# CTRL_MODULE_CORE register map
Vendor: Texas Instruments
Registers are 32-bit, access per field, reset 0x0 unless marked. A register's access mark holds for its fields unless they carry their own. Offsets are as the file gives them; [hi:lo] are bit positions; {n}, {i} and the like mark numbered series; 'fields as' and 'values as' point back to an identical list.

## CTRL_MODULE_CORE (part 5 of 12)
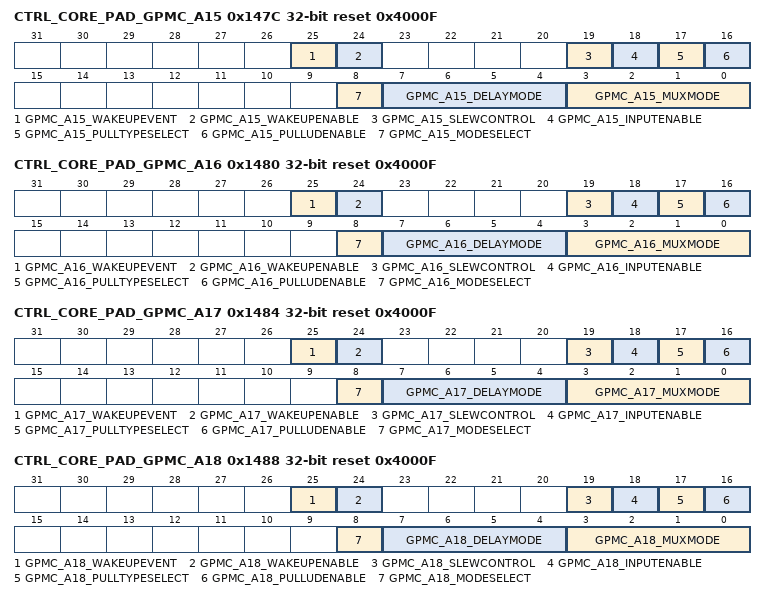
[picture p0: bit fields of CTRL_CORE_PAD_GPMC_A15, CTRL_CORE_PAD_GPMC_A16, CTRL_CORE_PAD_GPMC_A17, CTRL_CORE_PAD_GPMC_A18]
0x147C CTRL_CORE_PAD_GPMC_A15 reset 0x4000F
  [25] GPMC_A15_WAKEUPEVENT ro
    0=NOWAKEUP (No wakeup event detected); 1=WAKEUP (Wakeup event detected)
  [24] GPMC_A15_WAKEUPENABLE rw
    0=DISABLE (Wakeup is disabled); 1=ENABLE (Wakeup is enabled)
  [19] GPMC_A15_SLEWCONTROL rw
    0=FAST_SLEW (Fast slew is selected); 1=SLOW_SLEW (Slow slew is selected)
  [18] GPMC_A15_INPUTENABLE rw
    0=DISABLE (Receive mode is disabled); 1=ENABLE (Receive mode is enabled)
  [17] GPMC_A15_PULLTYPESELECT rw
    0=PULL_DOWN (Pull Down is selected); 1=PULL_UP (Pull Up is selected)
  [16] GPMC_A15_PULLUDENABLE rw
    0=ENABLE (Enables weak Pull Up/Down); 1=DISABLE (Disables weak Pull Up/Down)
  [8] GPMC_A15_MODESELECT rw — Selects between the Default IO Timing Mode and a Virtual or Manual IO Timing Mode. Refer to the device Data Manual for definition of the required settings for a given mode of operation. When this bit is 0b1, a Virtual IO Timing Mode can be selected via the DELAYMODE field of this register, as described in, Virtual IO Timing Modes. Manual IO Timing Modes are selected via the procedure described in , Manual IO Timing Modes.
    0=MUX_MODE (Default IO Timing Mode is used); 1=DELAY_MODE (A Virtual or Manual IO Timing Mode is used)
  [7:4] GPMC_A15_DELAYMODE rw — This bit field selects the Virtual Timing Mode used when the MODESELECT bit is set to 0b1. See, Virtual IO Timing Modes for details.
  [3:0] GPMC_A15_MUXMODE rw
    0=GPMC_A15; 1=QSPI1_D2; 4=VIN4A_D8; 7=TIMER5; 14=GPIO2_5; 15=DRIVER OFF
0x1480 CTRL_CORE_PAD_GPMC_A16 reset 0x4000F
  [25] GPMC_A16_WAKEUPEVENT ro
    values as CTRL_CORE_PAD_GPMC_A15.GPMC_A15_WAKEUPEVENT
  [24] GPMC_A16_WAKEUPENABLE rw
    0=DISABLE (Wakeup is disabled); 1=ENABLE (Wakeup is enabled)
  [19] GPMC_A16_SLEWCONTROL rw
    values as CTRL_CORE_PAD_GPMC_A15.GPMC_A15_SLEWCONTROL
  [18] GPMC_A16_INPUTENABLE rw
    values as CTRL_CORE_PAD_GPMC_A15.GPMC_A15_INPUTENABLE
  [17] GPMC_A16_PULLTYPESELECT rw
    values as CTRL_CORE_PAD_GPMC_A15.GPMC_A15_PULLTYPESELECT
  [16] GPMC_A16_PULLUDENABLE rw
    values as CTRL_CORE_PAD_GPMC_A15.GPMC_A15_PULLUDENABLE
  [8] GPMC_A16_MODESELECT rw — Selects between the Default IO Timing Mode and a Virtual or Manual IO Timing Mode. Refer to the device Data Manual for definition of the required settings for a given mode of operation. When this bit is 0b1, a Virtual IO Timing Mode can be selected via the DELAYMODE field of this register, as described in, Virtual IO Timing Modes. Manual IO Timing Modes are selected via the procedure described in , Manual IO Timing Modes.
    values as CTRL_CORE_PAD_GPMC_A15.GPMC_A15_MODESELECT
  [7:4] GPMC_A16_DELAYMODE rw — This bit field selects the Virtual Timing Mode used when the MODESELECT bit is set to 0b1. See, Virtual IO Timing Modes for details.
  [3:0] GPMC_A16_MUXMODE rw
    0=GPMC_A16; 1=QSPI1_D0; 4=VIN4A_D9; 14=GPIO2_6; 15=DRIVER OFF
0x1484 CTRL_CORE_PAD_GPMC_A17 reset 0x4000F
  [25] GPMC_A17_WAKEUPEVENT ro
    values as CTRL_CORE_PAD_GPMC_A15.GPMC_A15_WAKEUPEVENT
  [24] GPMC_A17_WAKEUPENABLE rw
    0=DISABLE (Wakeup is disabled); 1=ENABLE (Wakeup is enabled)
  [19] GPMC_A17_SLEWCONTROL rw
    values as CTRL_CORE_PAD_GPMC_A15.GPMC_A15_SLEWCONTROL
  [18] GPMC_A17_INPUTENABLE rw
    values as CTRL_CORE_PAD_GPMC_A15.GPMC_A15_INPUTENABLE
  [17] GPMC_A17_PULLTYPESELECT rw
    values as CTRL_CORE_PAD_GPMC_A15.GPMC_A15_PULLTYPESELECT
  [16] GPMC_A17_PULLUDENABLE rw
    values as CTRL_CORE_PAD_GPMC_A15.GPMC_A15_PULLUDENABLE
  [8] GPMC_A17_MODESELECT rw — Selects between the Default IO Timing Mode and a Virtual or Manual IO Timing Mode. Refer to the device Data Manual for definition of the required settings for a given mode of operation. When this bit is 0b1, a Virtual IO Timing Mode can be selected via the DELAYMODE field of this register, as described in, Virtual IO Timing Modes. Manual IO Timing Modes are selected via the procedure described in , Manual IO Timing Modes.
    values as CTRL_CORE_PAD_GPMC_A15.GPMC_A15_MODESELECT
  [7:4] GPMC_A17_DELAYMODE rw — This bit field selects the Virtual Timing Mode used when the MODESELECT bit is set to 0b1. See, Virtual IO Timing Modes for details.
  [3:0] GPMC_A17_MUXMODE rw
    0=GPMC_A17; 1=QSPI1_D1; 4=VIN4A_D10; 14=GPIO2_7; 15=DRIVER OFF
0x1488 CTRL_CORE_PAD_GPMC_A18 reset 0x4000F
  [25] GPMC_A18_WAKEUPEVENT ro
    values as CTRL_CORE_PAD_GPMC_A15.GPMC_A15_WAKEUPEVENT
  [24] GPMC_A18_WAKEUPENABLE rw
    0=DISABLE (Wakeup is disabled); 1=ENABLE (Wakeup is enabled)
  [19] GPMC_A18_SLEWCONTROL rw
    values as CTRL_CORE_PAD_GPMC_A15.GPMC_A15_SLEWCONTROL
  [18] GPMC_A18_INPUTENABLE rw
    values as CTRL_CORE_PAD_GPMC_A15.GPMC_A15_INPUTENABLE
  [17] GPMC_A18_PULLTYPESELECT rw
    values as CTRL_CORE_PAD_GPMC_A15.GPMC_A15_PULLTYPESELECT
  [16] GPMC_A18_PULLUDENABLE rw
    values as CTRL_CORE_PAD_GPMC_A15.GPMC_A15_PULLUDENABLE
  [8] GPMC_A18_MODESELECT rw — Selects between the Default IO Timing Mode and a Virtual or Manual IO Timing Mode. Refer to the device Data Manual for definition of the required settings for a given mode of operation. When this bit is 0b1, a Virtual IO Timing Mode can be selected via the DELAYMODE field of this register, as described in, Virtual IO Timing Modes. Manual IO Timing Modes are selected via the procedure described in , Manual IO Timing Modes.
    values as CTRL_CORE_PAD_GPMC_A15.GPMC_A15_MODESELECT
  [7:4] GPMC_A18_DELAYMODE rw — This bit field selects the Virtual Timing Mode used when the MODESELECT bit is set to 0b1. See, Virtual IO Timing Modes for details.
  [3:0] GPMC_A18_MUXMODE rw
    0=GPMC_A18; 1=QSPI1_SCLK; 4=VIN4A_D11; 14=GPIO2_8; 15=DRIVER OFF
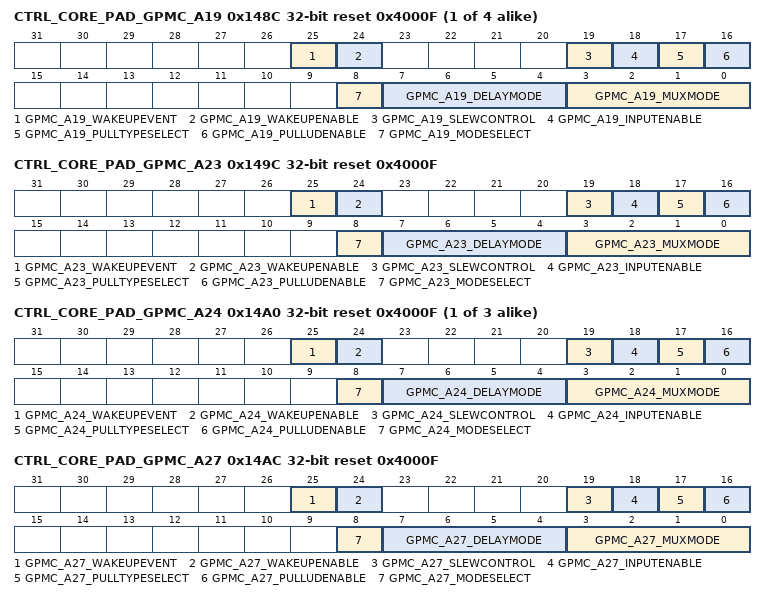
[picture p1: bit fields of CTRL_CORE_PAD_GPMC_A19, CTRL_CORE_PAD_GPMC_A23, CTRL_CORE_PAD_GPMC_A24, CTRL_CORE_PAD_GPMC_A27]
{0x1440+4i} CTRL_CORE_PAD_GPMC_A{i} reset 0x4000F (i=19..22)
  [25] GPMC_A{i}_WAKEUPEVENT ro
    values as CTRL_CORE_PAD_GPMC_A15.GPMC_A15_WAKEUPEVENT
  [24] GPMC_A{i}_WAKEUPENABLE rw
    0=DISABLE (Wakeup is disabled); 1=ENABLE (Wakeup is enabled)
  [19] GPMC_A{i}_SLEWCONTROL rw
    values as CTRL_CORE_PAD_GPMC_A15.GPMC_A15_SLEWCONTROL
  [18] GPMC_A{i}_INPUTENABLE rw
    values as CTRL_CORE_PAD_GPMC_A15.GPMC_A15_INPUTENABLE
  [17] GPMC_A{i}_PULLTYPESELECT rw
    values as CTRL_CORE_PAD_GPMC_A15.GPMC_A15_PULLTYPESELECT
  [16] GPMC_A{i}_PULLUDENABLE rw
    values as CTRL_CORE_PAD_GPMC_A15.GPMC_A15_PULLUDENABLE
  [8] GPMC_A{i}_MODESELECT rw — Selects between the Default IO Timing Mode and a Virtual or Manual IO Timing Mode. Refer to the device Data Manual for definition of the required settings for a given mode of operation. When this bit is 0b1, a Virtual IO Timing Mode can be selected via the DELAYMODE field of this register, as described in, Virtual IO Timing Modes. Manual IO Timing Modes are selected via the procedure described in , Manual IO Timing Modes.
    values as CTRL_CORE_PAD_GPMC_A15.GPMC_A15_MODESELECT
  [7:4] GPMC_A{i}_DELAYMODE rw — This bit field selects the Virtual Timing Mode used when the MODESELECT bit is set to 0b1. See, Virtual IO Timing Modes for details.
  [3:0] GPMC_A{i}_MUXMODE rw
    0=GPMC_A{i}; 1=MMC2_DAT{i-15}; 2=GPMC_A{i-6}; 4=VIN4A_D{i-7}; 6=VIN3B_D{i-19}; 14=GPIO2_{i-10}; 15=DRIVER OFF
0x149C CTRL_CORE_PAD_GPMC_A23 reset 0x4000F
  [25] GPMC_A23_WAKEUPEVENT ro
    values as CTRL_CORE_PAD_GPMC_A15.GPMC_A15_WAKEUPEVENT
  [24] GPMC_A23_WAKEUPENABLE rw
    0=DISABLE (Wakeup is disabled); 1=ENABLE (Wakeup is enabled)
  [19] GPMC_A23_SLEWCONTROL rw
    values as CTRL_CORE_PAD_GPMC_A15.GPMC_A15_SLEWCONTROL
  [18] GPMC_A23_INPUTENABLE rw
    values as CTRL_CORE_PAD_GPMC_A15.GPMC_A15_INPUTENABLE
  [17] GPMC_A23_PULLTYPESELECT rw
    values as CTRL_CORE_PAD_GPMC_A15.GPMC_A15_PULLTYPESELECT
  [16] GPMC_A23_PULLUDENABLE rw
    values as CTRL_CORE_PAD_GPMC_A15.GPMC_A15_PULLUDENABLE
  [8] GPMC_A23_MODESELECT rw — Selects between the Default IO Timing Mode and a Virtual or Manual IO Timing Mode. Refer to the device Data Manual for definition of the required settings for a given mode of operation. When this bit is 0b1, a Virtual IO Timing Mode can be selected via the DELAYMODE field of this register, as described in, Virtual IO Timing Modes. Manual IO Timing Modes are selected via the procedure described in , Manual IO Timing Modes.
    values as CTRL_CORE_PAD_GPMC_A15.GPMC_A15_MODESELECT
  [7:4] GPMC_A23_DELAYMODE rw — This bit field selects the Virtual Timing Mode used when the MODESELECT bit is set to 0b1. See, Virtual IO Timing Modes for details.
  [3:0] GPMC_A23_MUXMODE rw
    0=GPMC_A23; 1=MMC2_CLK; 2=GPMC_A17; 4=VIN4A_FLD0; 6=VIN3B_D4; 14=GPIO2_13; 15=DRIVER OFF
{0x1440+4i} CTRL_CORE_PAD_GPMC_A{i} reset 0x4000F (i=24..26)
  [25] GPMC_A{i}_WAKEUPEVENT ro
    values as CTRL_CORE_PAD_GPMC_A15.GPMC_A15_WAKEUPEVENT
  [24] GPMC_A{i}_WAKEUPENABLE rw
    0=DISABLE (Wakeup is disabled); 1=ENABLE (Wakeup is enabled)
  [19] GPMC_A{i}_SLEWCONTROL rw
    values as CTRL_CORE_PAD_GPMC_A15.GPMC_A15_SLEWCONTROL
  [18] GPMC_A{i}_INPUTENABLE rw
    values as CTRL_CORE_PAD_GPMC_A15.GPMC_A15_INPUTENABLE
  [17] GPMC_A{i}_PULLTYPESELECT rw
    values as CTRL_CORE_PAD_GPMC_A15.GPMC_A15_PULLTYPESELECT
  [16] GPMC_A{i}_PULLUDENABLE rw
    values as CTRL_CORE_PAD_GPMC_A15.GPMC_A15_PULLUDENABLE
  [8] GPMC_A{i}_MODESELECT rw — Selects between the Default IO Timing Mode and a Virtual or Manual IO Timing Mode. Refer to the device Data Manual for definition of the required settings for a given mode of operation. When this bit is 0b1, a Virtual IO Timing Mode can be selected via the DELAYMODE field of this register, as described in, Virtual IO Timing Modes. Manual IO Timing Modes are selected via the procedure described in , Manual IO Timing Modes.
    values as CTRL_CORE_PAD_GPMC_A15.GPMC_A15_MODESELECT
  [7:4] GPMC_A{i}_DELAYMODE rw — This bit field selects the Virtual Timing Mode used when the MODESELECT bit is set to 0b1. See, Virtual IO Timing Modes for details.
  [3:0] GPMC_A{i}_MUXMODE rw
    0=GPMC_A{i}; 1=MMC2_DAT{i-24}; 2=GPMC_A{i-6}; 6=VIN3B_D{i-19}; 14=GPIO2_{i-10}; 15=DRIVER OFF
0x14AC CTRL_CORE_PAD_GPMC_A27 reset 0x4000F
  [25] GPMC_A27_WAKEUPEVENT ro
    values as CTRL_CORE_PAD_GPMC_A15.GPMC_A15_WAKEUPEVENT
  [24] GPMC_A27_WAKEUPENABLE rw
    0=DISABLE (Wakeup is disabled); 1=ENABLE (Wakeup is enabled)
  [19] GPMC_A27_SLEWCONTROL rw
    values as CTRL_CORE_PAD_GPMC_A15.GPMC_A15_SLEWCONTROL
  [18] GPMC_A27_INPUTENABLE rw
    values as CTRL_CORE_PAD_GPMC_A15.GPMC_A15_INPUTENABLE
  [17] GPMC_A27_PULLTYPESELECT rw
    values as CTRL_CORE_PAD_GPMC_A15.GPMC_A15_PULLTYPESELECT
  [16] GPMC_A27_PULLUDENABLE rw
    values as CTRL_CORE_PAD_GPMC_A15.GPMC_A15_PULLUDENABLE
  [8] GPMC_A27_MODESELECT rw — Selects between the Default IO Timing Mode and a Virtual or Manual IO Timing Mode. Refer to the device Data Manual for definition of the required settings for a given mode of operation. When this bit is 0b1, a Virtual IO Timing Mode can be selected via the DELAYMODE field of this register, as described in, Virtual IO Timing Modes. Manual IO Timing Modes are selected via the procedure described in , Manual IO Timing Modes.
    values as CTRL_CORE_PAD_GPMC_A15.GPMC_A15_MODESELECT
  [7:4] GPMC_A27_DELAYMODE rw — This bit field selects the Virtual Timing Mode used when the MODESELECT bit is set to 0b1. See, Virtual IO Timing Modes for details.
  [3:0] GPMC_A27_MUXMODE rw
    0=GPMC_A27; 1=MMC2_DAT3; 2=GPMC_A21; 6=VIN3B_HSYNC1; 14=GPIO2_17; 15=DRIVER OFF
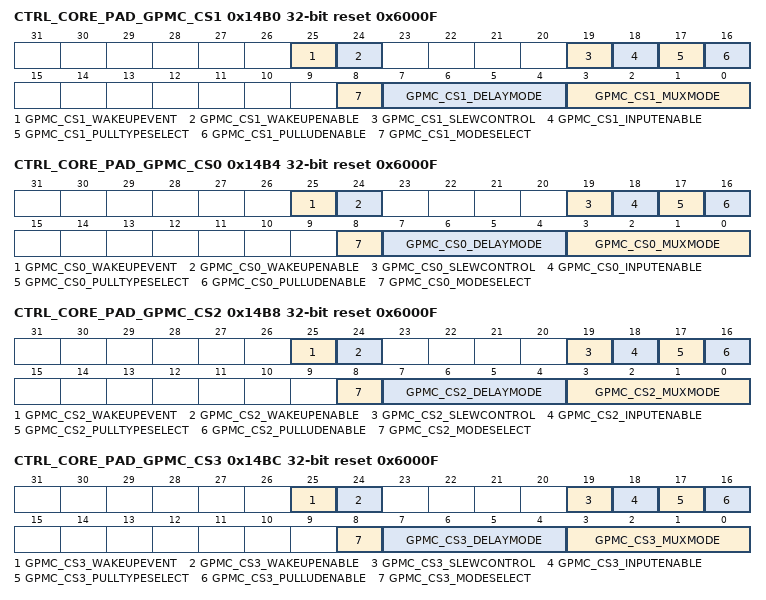
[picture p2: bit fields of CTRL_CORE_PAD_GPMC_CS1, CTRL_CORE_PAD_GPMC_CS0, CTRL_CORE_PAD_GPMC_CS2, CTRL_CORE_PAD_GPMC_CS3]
0x14B0 CTRL_CORE_PAD_GPMC_CS1 reset 0x6000F
  [25] GPMC_CS1_WAKEUPEVENT ro
    values as CTRL_CORE_PAD_GPMC_A15.GPMC_A15_WAKEUPEVENT
  [24] GPMC_CS1_WAKEUPENABLE rw
    0=DISABLE (Wakeup is disabled); 1=ENABLE (Wakeup is enabled)
  [19] GPMC_CS1_SLEWCONTROL rw
    values as CTRL_CORE_PAD_GPMC_A15.GPMC_A15_SLEWCONTROL
  [18] GPMC_CS1_INPUTENABLE rw
    values as CTRL_CORE_PAD_GPMC_A15.GPMC_A15_INPUTENABLE
  [17] GPMC_CS1_PULLTYPESELECT rw
    values as CTRL_CORE_PAD_GPMC_A15.GPMC_A15_PULLTYPESELECT
  [16] GPMC_CS1_PULLUDENABLE rw
    values as CTRL_CORE_PAD_GPMC_A15.GPMC_A15_PULLUDENABLE
  [8] GPMC_CS1_MODESELECT rw — Selects between the Default IO Timing Mode and a Virtual or Manual IO Timing Mode. Refer to the device Data Manual for definition of the required settings for a given mode of operation. When this bit is 0b1, a Virtual IO Timing Mode can be selected via the DELAYMODE field of this register, as described in, Virtual IO Timing Modes. Manual IO Timing Modes are selected via the procedure described in , Manual IO Timing Modes.
    values as CTRL_CORE_PAD_GPMC_A15.GPMC_A15_MODESELECT
  [7:4] GPMC_CS1_DELAYMODE rw — This bit field selects the Virtual Timing Mode used when the MODESELECT bit is set to 0b1. See, Virtual IO Timing Modes for details.
  [3:0] GPMC_CS1_MUXMODE rw
    0=GPMC_CS1; 1=MMC2_CMD; 2=GPMC_A22; 4=VIN4A_DE0; 6=VIN3B_VSYNC1; 14=GPIO2_18; 15=DRIVER OFF
0x14B4 CTRL_CORE_PAD_GPMC_CS0 reset 0x6000F
  [25] GPMC_CS0_WAKEUPEVENT ro
    values as CTRL_CORE_PAD_GPMC_A15.GPMC_A15_WAKEUPEVENT
  [24] GPMC_CS0_WAKEUPENABLE rw
    0=DISABLE (Wakeup is disabled); 1=ENABLE (Wakeup is enabled)
  [19] GPMC_CS0_SLEWCONTROL rw
    values as CTRL_CORE_PAD_GPMC_A15.GPMC_A15_SLEWCONTROL
  [18] GPMC_CS0_INPUTENABLE rw
    values as CTRL_CORE_PAD_GPMC_A15.GPMC_A15_INPUTENABLE
  [17] GPMC_CS0_PULLTYPESELECT rw
    values as CTRL_CORE_PAD_GPMC_A15.GPMC_A15_PULLTYPESELECT
  [16] GPMC_CS0_PULLUDENABLE rw
    values as CTRL_CORE_PAD_GPMC_A15.GPMC_A15_PULLUDENABLE
  [8] GPMC_CS0_MODESELECT rw — Selects between the Default IO Timing Mode and a Virtual or Manual IO Timing Mode. Refer to the device Data Manual for definition of the required settings for a given mode of operation. When this bit is 0b1, a Virtual IO Timing Mode can be selected via the DELAYMODE field of this register, as described in, Virtual IO Timing Modes. Manual IO Timing Modes are selected via the procedure described in , Manual IO Timing Modes.
    values as CTRL_CORE_PAD_GPMC_A15.GPMC_A15_MODESELECT
  [7:4] GPMC_CS0_DELAYMODE rw — This bit field selects the Virtual Timing Mode used when the MODESELECT bit is set to 0b1. See, Virtual IO Timing Modes for details.
  [3:0] GPMC_CS0_MUXMODE rw
    0=GPMC_CS0; 14=GPIO2_19; 15=DRIVER OFF
0x14B8 CTRL_CORE_PAD_GPMC_CS2 reset 0x6000F
  [25] GPMC_CS2_WAKEUPEVENT ro
    values as CTRL_CORE_PAD_GPMC_A15.GPMC_A15_WAKEUPEVENT
  [24] GPMC_CS2_WAKEUPENABLE rw
    0=DISABLE (Wakeup is disabled); 1=ENABLE (Wakeup is enabled)
  [19] GPMC_CS2_SLEWCONTROL rw
    values as CTRL_CORE_PAD_GPMC_A15.GPMC_A15_SLEWCONTROL
  [18] GPMC_CS2_INPUTENABLE rw
    values as CTRL_CORE_PAD_GPMC_A15.GPMC_A15_INPUTENABLE
  [17] GPMC_CS2_PULLTYPESELECT rw
    values as CTRL_CORE_PAD_GPMC_A15.GPMC_A15_PULLTYPESELECT
  [16] GPMC_CS2_PULLUDENABLE rw
    values as CTRL_CORE_PAD_GPMC_A15.GPMC_A15_PULLUDENABLE
  [8] GPMC_CS2_MODESELECT rw — Selects between the Default IO Timing Mode and a Virtual or Manual IO Timing Mode. Refer to the device Data Manual for definition of the required settings for a given mode of operation. When this bit is 0b1, a Virtual IO Timing Mode can be selected via the DELAYMODE field of this register, as described in, Virtual IO Timing Modes. Manual IO Timing Modes are selected via the procedure described in , Manual IO Timing Modes.
    values as CTRL_CORE_PAD_GPMC_A15.GPMC_A15_MODESELECT
  [7:4] GPMC_CS2_DELAYMODE rw — This bit field selects the Virtual Timing Mode used when the MODESELECT bit is set to 0b1. See, Virtual IO Timing Modes for details.
  [3:0] GPMC_CS2_MUXMODE rw
    0=GPMC_CS2; 1=QSPI1_CS0; 14=GPIO2_20; 15=DRIVER OFF
0x14BC CTRL_CORE_PAD_GPMC_CS3 reset 0x6000F
  [25] GPMC_CS3_WAKEUPEVENT ro
    values as CTRL_CORE_PAD_GPMC_A15.GPMC_A15_WAKEUPEVENT
  [24] GPMC_CS3_WAKEUPENABLE rw
    0=DISABLE (Wakeup is disabled); 1=ENABLE (Wakeup is enabled)
  [19] GPMC_CS3_SLEWCONTROL rw
    values as CTRL_CORE_PAD_GPMC_A15.GPMC_A15_SLEWCONTROL
  [18] GPMC_CS3_INPUTENABLE rw
    values as CTRL_CORE_PAD_GPMC_A15.GPMC_A15_INPUTENABLE
  [17] GPMC_CS3_PULLTYPESELECT rw
    values as CTRL_CORE_PAD_GPMC_A15.GPMC_A15_PULLTYPESELECT
  [16] GPMC_CS3_PULLUDENABLE rw
    values as CTRL_CORE_PAD_GPMC_A15.GPMC_A15_PULLUDENABLE
  [8] GPMC_CS3_MODESELECT rw — Selects between the Default IO Timing Mode and a Virtual or Manual IO Timing Mode. Refer to the device Data Manual for definition of the required settings for a given mode of operation. When this bit is 0b1, a Virtual IO Timing Mode can be selected via the DELAYMODE field of this register, as described in, Virtual IO Timing Modes. Manual IO Timing Modes are selected via the procedure described in , Manual IO Timing Modes.
    values as CTRL_CORE_PAD_GPMC_A15.GPMC_A15_MODESELECT
  [7:4] GPMC_CS3_DELAYMODE rw — This bit field selects the Virtual Timing Mode used when the MODESELECT bit is set to 0b1. See, Virtual IO Timing Modes for details.
  [3:0] GPMC_CS3_MUXMODE rw
    0=GPMC_CS3; 1=QSPI1_CS1; 2=VIN3A_CLK0; 3=VOUT3_CLK; 5=GPMC_A1; 14=GPIO2_21; 15=DRIVER OFF
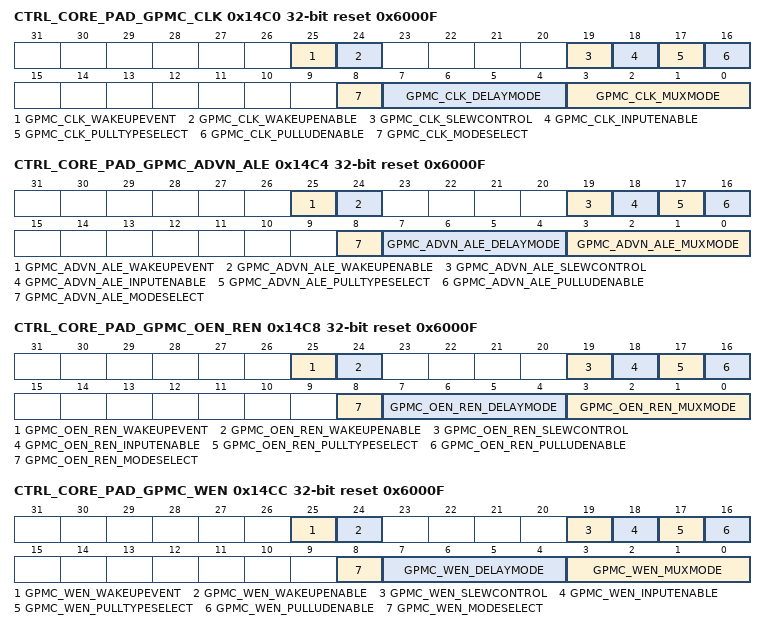
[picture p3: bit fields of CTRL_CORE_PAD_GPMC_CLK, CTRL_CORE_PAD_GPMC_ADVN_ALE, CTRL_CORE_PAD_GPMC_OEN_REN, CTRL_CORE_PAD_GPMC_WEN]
0x14C0 CTRL_CORE_PAD_GPMC_CLK reset 0x6000F
  [25] GPMC_CLK_WAKEUPEVENT ro
    values as CTRL_CORE_PAD_GPMC_A15.GPMC_A15_WAKEUPEVENT
  [24] GPMC_CLK_WAKEUPENABLE rw
    0=DISABLE (Wakeup is disabled); 1=ENABLE (Wakeup is enabled)
  [19] GPMC_CLK_SLEWCONTROL rw
    values as CTRL_CORE_PAD_GPMC_A15.GPMC_A15_SLEWCONTROL
  [18] GPMC_CLK_INPUTENABLE rw
    values as CTRL_CORE_PAD_GPMC_A15.GPMC_A15_INPUTENABLE
  [17] GPMC_CLK_PULLTYPESELECT rw
    values as CTRL_CORE_PAD_GPMC_A15.GPMC_A15_PULLTYPESELECT
  [16] GPMC_CLK_PULLUDENABLE rw
    values as CTRL_CORE_PAD_GPMC_A15.GPMC_A15_PULLUDENABLE
  [8] GPMC_CLK_MODESELECT rw — Selects between the Default IO Timing Mode and a Virtual or Manual IO Timing Mode. Refer to the device Data Manual for definition of the required settings for a given mode of operation. When this bit is 0b1, a Virtual IO Timing Mode can be selected via the DELAYMODE field of this register, as described in, Virtual IO Timing Modes. Manual IO Timing Modes are selected via the procedure described in , Manual IO Timing Modes.
    values as CTRL_CORE_PAD_GPMC_A15.GPMC_A15_MODESELECT
  [7:4] GPMC_CLK_DELAYMODE rw — This bit field selects the Virtual Timing Mode used when the MODESELECT bit is set to 0b1. See, Virtual IO Timing Modes for details.
  [3:0] GPMC_CLK_MUXMODE rw
    0=GPMC_CLK; 1=GPMC_CS7; 2=CLKOUT1; 3=GPMC_WAIT1; 4=VIN4A_HSYNC0; 5=VIN4A_DE0; 6=VIN3B_CLK1; 7=TIMER4; 8=I2C3_SCL; 9=DMA_EVT1; 14=GPIO2_22; 15=DRIVER OFF
0x14C4 CTRL_CORE_PAD_GPMC_ADVN_ALE reset 0x6000F
  [25] GPMC_ADVN_ALE_WAKEUPEVENT ro
    values as CTRL_CORE_PAD_GPMC_A15.GPMC_A15_WAKEUPEVENT
  [24] GPMC_ADVN_ALE_WAKEUPENABLE rw
    0=DISABLE (Wakeup is disabled); 1=ENABLE (Wakeup is enabled)
  [19] GPMC_ADVN_ALE_SLEWCONTROL rw
    values as CTRL_CORE_PAD_GPMC_A15.GPMC_A15_SLEWCONTROL
  [18] GPMC_ADVN_ALE_INPUTENABLE rw
    values as CTRL_CORE_PAD_GPMC_A15.GPMC_A15_INPUTENABLE
  [17] GPMC_ADVN_ALE_PULLTYPESELECT rw
    values as CTRL_CORE_PAD_GPMC_A15.GPMC_A15_PULLTYPESELECT
  [16] GPMC_ADVN_ALE_PULLUDENABLE rw
    values as CTRL_CORE_PAD_GPMC_A15.GPMC_A15_PULLUDENABLE
  [8] GPMC_ADVN_ALE_MODESELECT rw — Selects between the Default IO Timing Mode and a Virtual or Manual IO Timing Mode. Refer to the device Data Manual for definition of the required settings for a given mode of operation. When this bit is 0b1, a Virtual IO Timing Mode can be selected via the DELAYMODE field of this register, as described in, Virtual IO Timing Modes. Manual IO Timing Modes are selected via the procedure described in , Manual IO Timing Modes.
    values as CTRL_CORE_PAD_GPMC_A15.GPMC_A15_MODESELECT
  [7:4] GPMC_ADVN_ALE_DELAYMODE rw — This bit field selects the Virtual Timing Mode used when the MODESELECT bit is set to 0b1. See, Virtual IO Timing Modes for details.
  [3:0] GPMC_ADVN_ALE_MUXMODE rw
    0=GPMC_ADVN_ALE; 1=GPMC_CS6; 2=CLKOUT2; 3=GPMC_WAIT1; 4=VIN4A_VSYNC0; 5=GPMC_A2; 6=GPMC_A23; 7=TIMER3; 8=I2C3_SDA; 9=DMA_EVT2; 14=GPIO2_23; 15=DRIVER OFF
0x14C8 CTRL_CORE_PAD_GPMC_OEN_REN reset 0x6000F
  [25] GPMC_OEN_REN_WAKEUPEVENT ro
    values as CTRL_CORE_PAD_GPMC_A15.GPMC_A15_WAKEUPEVENT
  [24] GPMC_OEN_REN_WAKEUPENABLE rw
    0=DISABLE (Wakeup is disabled); 1=ENABLE (Wakeup is enabled)
  [19] GPMC_OEN_REN_SLEWCONTROL rw
    values as CTRL_CORE_PAD_GPMC_A15.GPMC_A15_SLEWCONTROL
  [18] GPMC_OEN_REN_INPUTENABLE rw
    values as CTRL_CORE_PAD_GPMC_A15.GPMC_A15_INPUTENABLE
  [17] GPMC_OEN_REN_PULLTYPESELECT rw
    values as CTRL_CORE_PAD_GPMC_A15.GPMC_A15_PULLTYPESELECT
  [16] GPMC_OEN_REN_PULLUDENABLE rw
    values as CTRL_CORE_PAD_GPMC_A15.GPMC_A15_PULLUDENABLE
  [8] GPMC_OEN_REN_MODESELECT rw — Selects between the Default IO Timing Mode and a Virtual or Manual IO Timing Mode. Refer to the device Data Manual for definition of the required settings for a given mode of operation. When this bit is 0b1, a Virtual IO Timing Mode can be selected via the DELAYMODE field of this register, as described in, Virtual IO Timing Modes. Manual IO Timing Modes are selected via the procedure described in , Manual IO Timing Modes.
    values as CTRL_CORE_PAD_GPMC_A15.GPMC_A15_MODESELECT
  [7:4] GPMC_OEN_REN_DELAYMODE rw — This bit field selects the Virtual Timing Mode used when the MODESELECT bit is set to 0b1. See, Virtual IO Timing Modes for details.
  [3:0] GPMC_OEN_REN_MUXMODE rw
    0=GPMC_OEN_REN; 14=GPIO2_24; 15=DRIVER OFF
0x14CC CTRL_CORE_PAD_GPMC_WEN reset 0x6000F
  [25] GPMC_WEN_WAKEUPEVENT ro
    values as CTRL_CORE_PAD_GPMC_A15.GPMC_A15_WAKEUPEVENT
  [24] GPMC_WEN_WAKEUPENABLE rw
    0=DISABLE (Wakeup is disabled); 1=ENABLE (Wakeup is enabled)
  [19] GPMC_WEN_SLEWCONTROL rw
    values as CTRL_CORE_PAD_GPMC_A15.GPMC_A15_SLEWCONTROL
  [18] GPMC_WEN_INPUTENABLE rw
    values as CTRL_CORE_PAD_GPMC_A15.GPMC_A15_INPUTENABLE
  [17] GPMC_WEN_PULLTYPESELECT rw
    values as CTRL_CORE_PAD_GPMC_A15.GPMC_A15_PULLTYPESELECT
  [16] GPMC_WEN_PULLUDENABLE rw
    values as CTRL_CORE_PAD_GPMC_A15.GPMC_A15_PULLUDENABLE
  [8] GPMC_WEN_MODESELECT rw — Selects between the Default IO Timing Mode and a Virtual or Manual IO Timing Mode. Refer to the device Data Manual for definition of the required settings for a given mode of operation. When this bit is 0b1, a Virtual IO Timing Mode can be selected via the DELAYMODE field of this register, as described in, Virtual IO Timing Modes. Manual IO Timing Modes are selected via the procedure described in , Manual IO Timing Modes.
    values as CTRL_CORE_PAD_GPMC_A15.GPMC_A15_MODESELECT
  [7:4] GPMC_WEN_DELAYMODE rw — This bit field selects the Virtual Timing Mode used when the MODESELECT bit is set to 0b1. See, Virtual IO Timing Modes for details.
  [3:0] GPMC_WEN_MUXMODE rw
    0=GPMC_WEN; 14=GPIO2_25; 15=DRIVER OFF
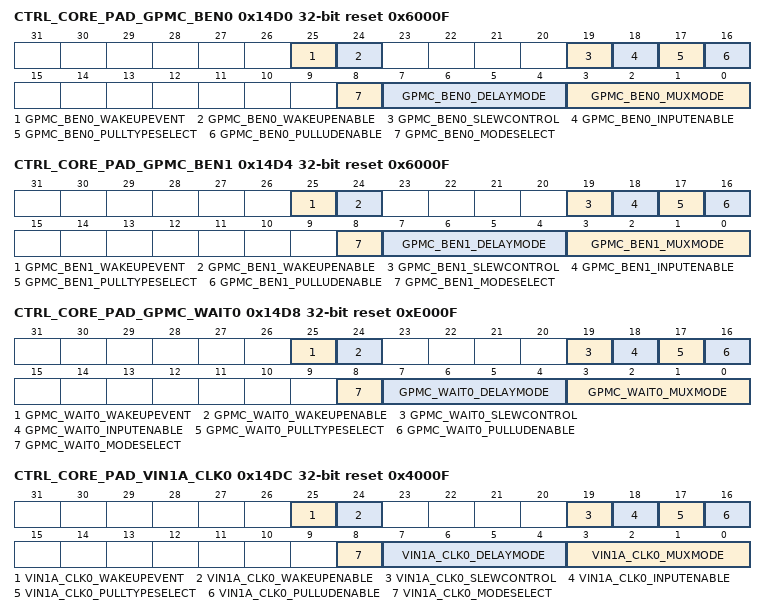
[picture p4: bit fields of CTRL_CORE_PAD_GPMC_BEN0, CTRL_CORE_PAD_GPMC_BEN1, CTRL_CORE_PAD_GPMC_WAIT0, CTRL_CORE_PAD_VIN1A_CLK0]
0x14D0 CTRL_CORE_PAD_GPMC_BEN0 reset 0x6000F
  [25] GPMC_BEN0_WAKEUPEVENT ro
    values as CTRL_CORE_PAD_GPMC_A15.GPMC_A15_WAKEUPEVENT
  [24] GPMC_BEN0_WAKEUPENABLE rw
    0=DISABLE (Wakeup is disabled); 1=ENABLE (Wakeup is enabled)
  [19] GPMC_BEN0_SLEWCONTROL rw
    values as CTRL_CORE_PAD_GPMC_A15.GPMC_A15_SLEWCONTROL
  [18] GPMC_BEN0_INPUTENABLE rw
    values as CTRL_CORE_PAD_GPMC_A15.GPMC_A15_INPUTENABLE
  [17] GPMC_BEN0_PULLTYPESELECT rw
    values as CTRL_CORE_PAD_GPMC_A15.GPMC_A15_PULLTYPESELECT
  [16] GPMC_BEN0_PULLUDENABLE rw
    values as CTRL_CORE_PAD_GPMC_A15.GPMC_A15_PULLUDENABLE
  [8] GPMC_BEN0_MODESELECT rw — Selects between the Default IO Timing Mode and a Virtual or Manual IO Timing Mode. Refer to the device Data Manual for definition of the required settings for a given mode of operation. When this bit is 0b1, a Virtual IO Timing Mode can be selected via the DELAYMODE field of this register, as described in, Virtual IO Timing Modes. Manual IO Timing Modes are selected via the procedure described in , Manual IO Timing Modes.
    values as CTRL_CORE_PAD_GPMC_A15.GPMC_A15_MODESELECT
  [7:4] GPMC_BEN0_DELAYMODE rw — This bit field selects the Virtual Timing Mode used when the MODESELECT bit is set to 0b1. See, Virtual IO Timing Modes for details.
  [3:0] GPMC_BEN0_MUXMODE rw
    0=GPMC_BEN0; 1=GPMC_CS4; 3=VIN1B_HSYNC1; 6=VIN3B_DE1; 7=TIMER2; 9=DMA_EVT3; 14=GPIO2_26; 15=DRIVER OFF
0x14D4 CTRL_CORE_PAD_GPMC_BEN1 reset 0x6000F
  [25] GPMC_BEN1_WAKEUPEVENT ro
    values as CTRL_CORE_PAD_GPMC_A15.GPMC_A15_WAKEUPEVENT
  [24] GPMC_BEN1_WAKEUPENABLE rw
    0=DISABLE (Wakeup is disabled); 1=ENABLE (Wakeup is enabled)
  [19] GPMC_BEN1_SLEWCONTROL rw
    values as CTRL_CORE_PAD_GPMC_A15.GPMC_A15_SLEWCONTROL
  [18] GPMC_BEN1_INPUTENABLE rw
    values as CTRL_CORE_PAD_GPMC_A15.GPMC_A15_INPUTENABLE
  [17] GPMC_BEN1_PULLTYPESELECT rw
    values as CTRL_CORE_PAD_GPMC_A15.GPMC_A15_PULLTYPESELECT
  [16] GPMC_BEN1_PULLUDENABLE rw
    values as CTRL_CORE_PAD_GPMC_A15.GPMC_A15_PULLUDENABLE
  [8] GPMC_BEN1_MODESELECT rw — Selects between the Default IO Timing Mode and a Virtual or Manual IO Timing Mode. Refer to the device Data Manual for definition of the required settings for a given mode of operation. When this bit is 0b1, a Virtual IO Timing Mode can be selected via the DELAYMODE field of this register, as described in, Virtual IO Timing Modes. Manual IO Timing Modes are selected via the procedure described in , Manual IO Timing Modes.
    values as CTRL_CORE_PAD_GPMC_A15.GPMC_A15_MODESELECT
  [7:4] GPMC_BEN1_DELAYMODE rw — This bit field selects the Virtual Timing Mode used when the MODESELECT bit is set to 0b1. See, Virtual IO Timing Modes for details.
  [3:0] GPMC_BEN1_MUXMODE rw
    0=GPMC_BEN1; 1=GPMC_CS5; 3=VIN1B_DE1; 4=VIN3B_CLK1; 5=GPMC_A3; 6=VIN3B_FLD1; 7=TIMER1; 9=DMA_EVT4; 14=GPIO2_27; 15=DRIVER OFF
0x14D8 CTRL_CORE_PAD_GPMC_WAIT0 reset 0xE000F
  [25] GPMC_WAIT0_WAKEUPEVENT ro
    values as CTRL_CORE_PAD_GPMC_A15.GPMC_A15_WAKEUPEVENT
  [24] GPMC_WAIT0_WAKEUPENABLE rw
    0=DISABLE (Wakeup is disabled); 1=ENABLE (Wakeup is enabled)
  [19] GPMC_WAIT0_SLEWCONTROL rw
    values as CTRL_CORE_PAD_GPMC_A15.GPMC_A15_SLEWCONTROL
  [18] GPMC_WAIT0_INPUTENABLE rw
    values as CTRL_CORE_PAD_GPMC_A15.GPMC_A15_INPUTENABLE
  [17] GPMC_WAIT0_PULLTYPESELECT rw
    values as CTRL_CORE_PAD_GPMC_A15.GPMC_A15_PULLTYPESELECT
  [16] GPMC_WAIT0_PULLUDENABLE rw
    values as CTRL_CORE_PAD_GPMC_A15.GPMC_A15_PULLUDENABLE
  [8] GPMC_WAIT0_MODESELECT rw — Selects between the Default IO Timing Mode and a Virtual or Manual IO Timing Mode. Refer to the device Data Manual for definition of the required settings for a given mode of operation. When this bit is 0b1, a Virtual IO Timing Mode can be selected via the DELAYMODE field of this register, as described in, Virtual IO Timing Modes. Manual IO Timing Modes are selected via the procedure described in , Manual IO Timing Modes.
    values as CTRL_CORE_PAD_GPMC_A15.GPMC_A15_MODESELECT
  [7:4] GPMC_WAIT0_DELAYMODE rw — This bit field selects the Virtual Timing Mode used when the MODESELECT bit is set to 0b1. See, Virtual IO Timing Modes for details.
  [3:0] GPMC_WAIT0_MUXMODE rw
    0=GPMC_WAIT0; 14=GPIO2_28; 15=DRIVER OFF
0x14DC CTRL_CORE_PAD_VIN1A_CLK0 reset 0x4000F
  [25] VIN1A_CLK0_WAKEUPEVENT ro
    values as CTRL_CORE_PAD_GPMC_A15.GPMC_A15_WAKEUPEVENT
  [24] VIN1A_CLK0_WAKEUPENABLE rw
    0=DISABLE (Wakeup is disabled); 1=ENABLE (Wakeup is enabled)
  [19] VIN1A_CLK0_SLEWCONTROL rw
    values as CTRL_CORE_PAD_GPMC_A15.GPMC_A15_SLEWCONTROL
  [18] VIN1A_CLK0_INPUTENABLE rw
    values as CTRL_CORE_PAD_GPMC_A15.GPMC_A15_INPUTENABLE
  [17] VIN1A_CLK0_PULLTYPESELECT rw
    values as CTRL_CORE_PAD_GPMC_A15.GPMC_A15_PULLTYPESELECT
  [16] VIN1A_CLK0_PULLUDENABLE rw
    values as CTRL_CORE_PAD_GPMC_A15.GPMC_A15_PULLUDENABLE
  [8] VIN1A_CLK0_MODESELECT rw — Selects between the Default IO Timing Mode and a Virtual or Manual IO Timing Mode. Refer to the device Data Manual for definition of the required settings for a given mode of operation. When this bit is 0b1, a Virtual IO Timing Mode can be selected via the DELAYMODE field of this register, as described in, Virtual IO Timing Modes. Manual IO Timing Modes are selected via the procedure described in , Manual IO Timing Modes.
    values as CTRL_CORE_PAD_GPMC_A15.GPMC_A15_MODESELECT
  [7:4] VIN1A_CLK0_DELAYMODE rw — This bit field selects the Virtual Timing Mode used when the MODESELECT bit is set to 0b1. See, Virtual IO Timing Modes for details.
  [3:0] VIN1A_CLK0_MUXMODE rw
    0=VIN1A_CLK0; 3=VOUT3_D16; 4=VOUT3_FLD; 14=GPIO2_30; 15=DRIVER OFF
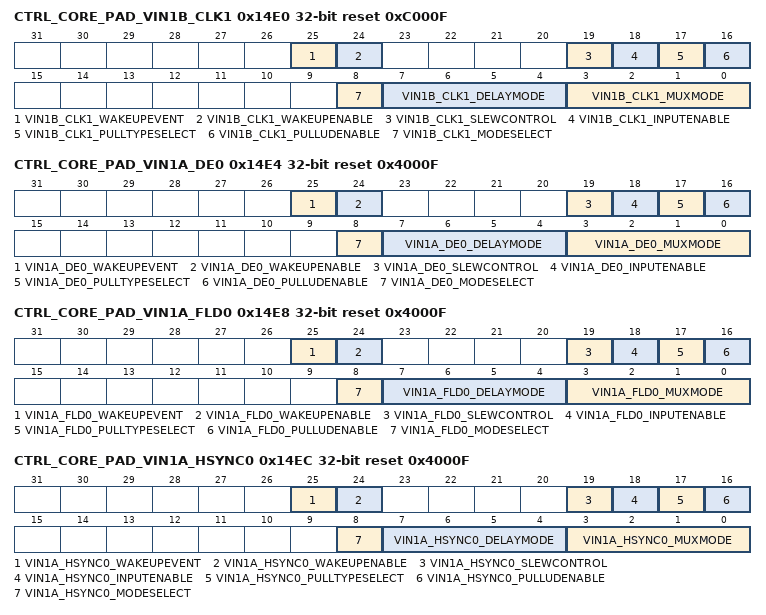
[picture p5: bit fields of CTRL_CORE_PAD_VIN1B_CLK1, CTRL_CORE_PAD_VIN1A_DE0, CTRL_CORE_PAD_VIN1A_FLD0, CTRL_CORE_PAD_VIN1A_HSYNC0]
0x14E0 CTRL_CORE_PAD_VIN1B_CLK1 reset 0xC000F
  [25] VIN1B_CLK1_WAKEUPEVENT ro
    values as CTRL_CORE_PAD_GPMC_A15.GPMC_A15_WAKEUPEVENT
  [24] VIN1B_CLK1_WAKEUPENABLE rw
    0=DISABLE (Wakeup is disabled); 1=ENABLE (Wakeup is enabled)
  [19] VIN1B_CLK1_SLEWCONTROL rw
    values as CTRL_CORE_PAD_GPMC_A15.GPMC_A15_SLEWCONTROL
  [18] VIN1B_CLK1_INPUTENABLE rw
    values as CTRL_CORE_PAD_GPMC_A15.GPMC_A15_INPUTENABLE
  [17] VIN1B_CLK1_PULLTYPESELECT rw
    values as CTRL_CORE_PAD_GPMC_A15.GPMC_A15_PULLTYPESELECT
  [16] VIN1B_CLK1_PULLUDENABLE rw
    values as CTRL_CORE_PAD_GPMC_A15.GPMC_A15_PULLUDENABLE
  [8] VIN1B_CLK1_MODESELECT rw — Selects between the Default IO Timing Mode and a Virtual or Manual IO Timing Mode. Refer to the device Data Manual for definition of the required settings for a given mode of operation. When this bit is 0b1, a Virtual IO Timing Mode can be selected via the DELAYMODE field of this register, as described in, Virtual IO Timing Modes. Manual IO Timing Modes are selected via the procedure described in , Manual IO Timing Modes.
    values as CTRL_CORE_PAD_GPMC_A15.GPMC_A15_MODESELECT
  [7:4] VIN1B_CLK1_DELAYMODE rw — This bit field selects the Virtual Timing Mode used when the MODESELECT bit is set to 0b1. See, Virtual IO Timing Modes for details.
  [3:0] VIN1B_CLK1_MUXMODE rw
    0=VIN1B_CLK1; 6=VIN3A_CLK0; 14=GPIO2_31; 15=DRIVER OFF
0x14E4 CTRL_CORE_PAD_VIN1A_DE0 reset 0x4000F
  [25] VIN1A_DE0_WAKEUPEVENT ro
    values as CTRL_CORE_PAD_GPMC_A15.GPMC_A15_WAKEUPEVENT
  [24] VIN1A_DE0_WAKEUPENABLE rw
    0=DISABLE (Wakeup is disabled); 1=ENABLE (Wakeup is enabled)
  [19] VIN1A_DE0_SLEWCONTROL rw
    values as CTRL_CORE_PAD_GPMC_A15.GPMC_A15_SLEWCONTROL
  [18] VIN1A_DE0_INPUTENABLE rw
    values as CTRL_CORE_PAD_GPMC_A15.GPMC_A15_INPUTENABLE
  [17] VIN1A_DE0_PULLTYPESELECT rw
    values as CTRL_CORE_PAD_GPMC_A15.GPMC_A15_PULLTYPESELECT
  [16] VIN1A_DE0_PULLUDENABLE rw
    values as CTRL_CORE_PAD_GPMC_A15.GPMC_A15_PULLUDENABLE
  [8] VIN1A_DE0_MODESELECT rw — Selects between the Default IO Timing Mode and a Virtual or Manual IO Timing Mode. Refer to the device Data Manual for definition of the required settings for a given mode of operation. When this bit is 0b1, a Virtual IO Timing Mode can be selected via the DELAYMODE field of this register, as described in, Virtual IO Timing Modes. Manual IO Timing Modes are selected via the procedure described in , Manual IO Timing Modes.
    values as CTRL_CORE_PAD_GPMC_A15.GPMC_A15_MODESELECT
  [7:4] VIN1A_DE0_DELAYMODE rw — This bit field selects the Virtual Timing Mode used when the MODESELECT bit is set to 0b1. See, Virtual IO Timing Modes for details.
  [3:0] VIN1A_DE0_MUXMODE rw
    0=VIN1A_DE0; 1=VIN1B_HSYNC1; 3=VOUT3_D17; 4=VOUT3_DE; 5=UART7_RXD; 7=TIMER16; 8=SPI3_SCLK; 9=KBD_ROW0; 10=EQEP1A_IN; 14=GPIO3_0; 15=DRIVER OFF
0x14E8 CTRL_CORE_PAD_VIN1A_FLD0 reset 0x4000F
  [25] VIN1A_FLD0_WAKEUPEVENT ro
    values as CTRL_CORE_PAD_GPMC_A15.GPMC_A15_WAKEUPEVENT
  [24] VIN1A_FLD0_WAKEUPENABLE rw
    0=DISABLE (Wakeup is disabled); 1=ENABLE (Wakeup is enabled)
  [19] VIN1A_FLD0_SLEWCONTROL rw
    values as CTRL_CORE_PAD_GPMC_A15.GPMC_A15_SLEWCONTROL
  [18] VIN1A_FLD0_INPUTENABLE rw
    values as CTRL_CORE_PAD_GPMC_A15.GPMC_A15_INPUTENABLE
  [17] VIN1A_FLD0_PULLTYPESELECT rw
    values as CTRL_CORE_PAD_GPMC_A15.GPMC_A15_PULLTYPESELECT
  [16] VIN1A_FLD0_PULLUDENABLE rw
    values as CTRL_CORE_PAD_GPMC_A15.GPMC_A15_PULLUDENABLE
  [8] VIN1A_FLD0_MODESELECT rw — Selects between the Default IO Timing Mode and a Virtual or Manual IO Timing Mode. Refer to the device Data Manual for definition of the required settings for a given mode of operation. When this bit is 0b1, a Virtual IO Timing Mode can be selected via the DELAYMODE field of this register, as described in, Virtual IO Timing Modes. Manual IO Timing Modes are selected via the procedure described in , Manual IO Timing Modes.
    values as CTRL_CORE_PAD_GPMC_A15.GPMC_A15_MODESELECT
  [7:4] VIN1A_FLD0_DELAYMODE rw — This bit field selects the Virtual Timing Mode used when the MODESELECT bit is set to 0b1. See, Virtual IO Timing Modes for details.
  [3:0] VIN1A_FLD0_MUXMODE rw
    0=VIN1A_FLD0; 1=VIN1B_VSYNC1; 4=VOUT3_CLK; 5=UART7_TXD; 7=TIMER15; 8=SPI3_D1; 9=KBD_ROW1; 10=EQEP1B_IN; 14=GPIO3_1; 15=DRIVER OFF
0x14EC CTRL_CORE_PAD_VIN1A_HSYNC0 reset 0x4000F
  [25] VIN1A_HSYNC0_WAKEUPEVENT ro
    values as CTRL_CORE_PAD_GPMC_A15.GPMC_A15_WAKEUPEVENT
  [24] VIN1A_HSYNC0_WAKEUPENABLE rw
    0=DISABLE (Wakeup is disabled); 1=ENABLE (Wakeup is enabled)
  [19] VIN1A_HSYNC0_SLEWCONTROL rw
    values as CTRL_CORE_PAD_GPMC_A15.GPMC_A15_SLEWCONTROL
  [18] VIN1A_HSYNC0_INPUTENABLE rw
    values as CTRL_CORE_PAD_GPMC_A15.GPMC_A15_INPUTENABLE
  [17] VIN1A_HSYNC0_PULLTYPESELECT rw
    values as CTRL_CORE_PAD_GPMC_A15.GPMC_A15_PULLTYPESELECT
  [16] VIN1A_HSYNC0_PULLUDENABLE rw
    values as CTRL_CORE_PAD_GPMC_A15.GPMC_A15_PULLUDENABLE
  [8] VIN1A_HSYNC0_MODESELECT rw — Selects between the Default IO Timing Mode and a Virtual or Manual IO Timing Mode. Refer to the device Data Manual for definition of the required settings for a given mode of operation. When this bit is 0b1, a Virtual IO Timing Mode can be selected via the DELAYMODE field of this register, as described in, Virtual IO Timing Modes. Manual IO Timing Modes are selected via the procedure described in , Manual IO Timing Modes.
    values as CTRL_CORE_PAD_GPMC_A15.GPMC_A15_MODESELECT
  [7:4] VIN1A_HSYNC0_DELAYMODE rw — This bit field selects the Virtual Timing Mode used when the MODESELECT bit is set to 0b1. See, Virtual IO Timing Modes for details.
  [3:0] VIN1A_HSYNC0_MUXMODE rw
    0=VIN1A_HSYNC0; 1=VIN1B_FLD1; 4=VOUT3_HSYNC; 5=UART7_CTSN; 7=TIMER14; 8=SPI3_D0; 10=EQEP1_INDEX; 14=GPIO3_2; 15=DRIVER OFF
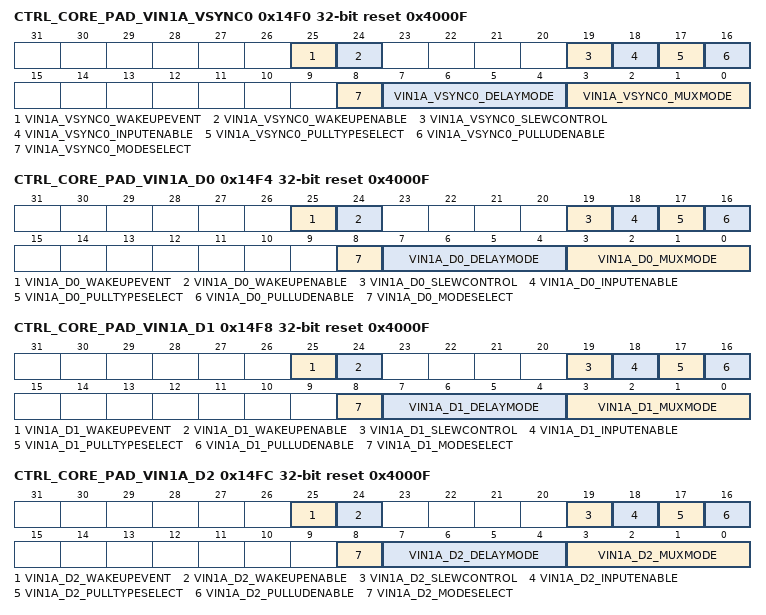
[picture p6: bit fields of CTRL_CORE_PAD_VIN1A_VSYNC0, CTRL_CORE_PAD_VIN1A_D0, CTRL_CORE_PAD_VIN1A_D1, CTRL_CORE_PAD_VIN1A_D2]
0x14F0 CTRL_CORE_PAD_VIN1A_VSYNC0 reset 0x4000F
  [25] VIN1A_VSYNC0_WAKEUPEVENT ro
    values as CTRL_CORE_PAD_GPMC_A15.GPMC_A15_WAKEUPEVENT
  [24] VIN1A_VSYNC0_WAKEUPENABLE rw
    0=DISABLE (Wakeup is disabled); 1=ENABLE (Wakeup is enabled)
  [19] VIN1A_VSYNC0_SLEWCONTROL rw
    values as CTRL_CORE_PAD_GPMC_A15.GPMC_A15_SLEWCONTROL
  [18] VIN1A_VSYNC0_INPUTENABLE rw
    values as CTRL_CORE_PAD_GPMC_A15.GPMC_A15_INPUTENABLE
  [17] VIN1A_VSYNC0_PULLTYPESELECT rw
    values as CTRL_CORE_PAD_GPMC_A15.GPMC_A15_PULLTYPESELECT
  [16] VIN1A_VSYNC0_PULLUDENABLE rw
    values as CTRL_CORE_PAD_GPMC_A15.GPMC_A15_PULLUDENABLE
  [8] VIN1A_VSYNC0_MODESELECT rw — Selects between the Default IO Timing Mode and a Virtual or Manual IO Timing Mode. Refer to the device Data Manual for definition of the required settings for a given mode of operation. When this bit is 0b1, a Virtual IO Timing Mode can be selected via the DELAYMODE field of this register, as described in, Virtual IO Timing Modes. Manual IO Timing Modes are selected via the procedure described in , Manual IO Timing Modes.
    values as CTRL_CORE_PAD_GPMC_A15.GPMC_A15_MODESELECT
  [7:4] VIN1A_VSYNC0_DELAYMODE rw — This bit field selects the Virtual Timing Mode used when the MODESELECT bit is set to 0b1. See, Virtual IO Timing Modes for details.
  [3:0] VIN1A_VSYNC0_MUXMODE rw
    0=VIN1A_VSYNC0; 1=VIN1B_DE1; 4=VOUT3_VSYNC; 5=UART7_RTSN; 7=TIMER13; 8=SPI3_CS0; 10=EQEP1_STROBE; 14=GPIO3_3; 15=DRIVER OFF
0x14F4 CTRL_CORE_PAD_VIN1A_D0 reset 0x4000F
  [25] VIN1A_D0_WAKEUPEVENT ro
    values as CTRL_CORE_PAD_GPMC_A15.GPMC_A15_WAKEUPEVENT
  [24] VIN1A_D0_WAKEUPENABLE rw
    0=DISABLE (Wakeup is disabled); 1=ENABLE (Wakeup is enabled)
  [19] VIN1A_D0_SLEWCONTROL rw
    values as CTRL_CORE_PAD_GPMC_A15.GPMC_A15_SLEWCONTROL
  [18] VIN1A_D0_INPUTENABLE rw
    values as CTRL_CORE_PAD_GPMC_A15.GPMC_A15_INPUTENABLE
  [17] VIN1A_D0_PULLTYPESELECT rw
    values as CTRL_CORE_PAD_GPMC_A15.GPMC_A15_PULLTYPESELECT
  [16] VIN1A_D0_PULLUDENABLE rw
    values as CTRL_CORE_PAD_GPMC_A15.GPMC_A15_PULLUDENABLE
  [8] VIN1A_D0_MODESELECT rw — Selects between the Default IO Timing Mode and a Virtual or Manual IO Timing Mode. Refer to the device Data Manual for definition of the required settings for a given mode of operation. When this bit is 0b1, a Virtual IO Timing Mode can be selected via the DELAYMODE field of this register, as described in, Virtual IO Timing Modes. Manual IO Timing Modes are selected via the procedure described in , Manual IO Timing Modes.
    values as CTRL_CORE_PAD_GPMC_A15.GPMC_A15_MODESELECT
  [7:4] VIN1A_D0_DELAYMODE rw — This bit field selects the Virtual Timing Mode used when the MODESELECT bit is set to 0b1. See, Virtual IO Timing Modes for details.
  [3:0] VIN1A_D0_MUXMODE rw
    0=VIN1A_D0; 3=VOUT3_D7; 4=VOUT3_D23; 5=UART8_RXD; 10=EHRPWM1A; 14=GPIO3_4; 15=DRIVER OFF
0x14F8 CTRL_CORE_PAD_VIN1A_D1 reset 0x4000F
  [25] VIN1A_D1_WAKEUPEVENT ro
    values as CTRL_CORE_PAD_GPMC_A15.GPMC_A15_WAKEUPEVENT
  [24] VIN1A_D1_WAKEUPENABLE rw
    0=DISABLE (Wakeup is disabled); 1=ENABLE (Wakeup is enabled)
  [19] VIN1A_D1_SLEWCONTROL rw
    values as CTRL_CORE_PAD_GPMC_A15.GPMC_A15_SLEWCONTROL
  [18] VIN1A_D1_INPUTENABLE rw
    values as CTRL_CORE_PAD_GPMC_A15.GPMC_A15_INPUTENABLE
  [17] VIN1A_D1_PULLTYPESELECT rw
    values as CTRL_CORE_PAD_GPMC_A15.GPMC_A15_PULLTYPESELECT
  [16] VIN1A_D1_PULLUDENABLE rw
    values as CTRL_CORE_PAD_GPMC_A15.GPMC_A15_PULLUDENABLE
  [8] VIN1A_D1_MODESELECT rw — Selects between the Default IO Timing Mode and a Virtual or Manual IO Timing Mode. Refer to the device Data Manual for definition of the required settings for a given mode of operation. When this bit is 0b1, a Virtual IO Timing Mode can be selected via the DELAYMODE field of this register, as described in, Virtual IO Timing Modes. Manual IO Timing Modes are selected via the procedure described in , Manual IO Timing Modes.
    values as CTRL_CORE_PAD_GPMC_A15.GPMC_A15_MODESELECT
  [7:4] VIN1A_D1_DELAYMODE rw — This bit field selects the Virtual Timing Mode used when the MODESELECT bit is set to 0b1. See, Virtual IO Timing Modes for details.
  [3:0] VIN1A_D1_MUXMODE rw
    0=VIN1A_D1; 3=VOUT3_D6; 4=VOUT3_D22; 5=UART8_TXD; 10=EHRPWM1B; 14=GPIO3_5; 15=DRIVER OFF
0x14FC CTRL_CORE_PAD_VIN1A_D2 reset 0x4000F
  [25] VIN1A_D2_WAKEUPEVENT ro
    values as CTRL_CORE_PAD_GPMC_A15.GPMC_A15_WAKEUPEVENT
  [24] VIN1A_D2_WAKEUPENABLE rw
    0=DISABLE (Wakeup is disabled); 1=ENABLE (Wakeup is enabled)
  [19] VIN1A_D2_SLEWCONTROL rw
    values as CTRL_CORE_PAD_GPMC_A15.GPMC_A15_SLEWCONTROL
  [18] VIN1A_D2_INPUTENABLE rw
    values as CTRL_CORE_PAD_GPMC_A15.GPMC_A15_INPUTENABLE
  [17] VIN1A_D2_PULLTYPESELECT rw
    values as CTRL_CORE_PAD_GPMC_A15.GPMC_A15_PULLTYPESELECT
  [16] VIN1A_D2_PULLUDENABLE rw
    values as CTRL_CORE_PAD_GPMC_A15.GPMC_A15_PULLUDENABLE
  [8] VIN1A_D2_MODESELECT rw — Selects between the Default IO Timing Mode and a Virtual or Manual IO Timing Mode. Refer to the device Data Manual for definition of the required settings for a given mode of operation. When this bit is 0b1, a Virtual IO Timing Mode can be selected via the DELAYMODE field of this register, as described in, Virtual IO Timing Modes. Manual IO Timing Modes are selected via the procedure described in , Manual IO Timing Modes.
    values as CTRL_CORE_PAD_GPMC_A15.GPMC_A15_MODESELECT
  [7:4] VIN1A_D2_DELAYMODE rw — This bit field selects the Virtual Timing Mode used when the MODESELECT bit is set to 0b1. See, Virtual IO Timing Modes for details.
  [3:0] VIN1A_D2_MUXMODE rw
    0=VIN1A_D2; 3=VOUT3_D5; 4=VOUT3_D21; 5=UART8_CTSN; 10=EHRPWM1_TRIPZONE_INPUT; 14=GPIO3_6; 15=DRIVER OFF
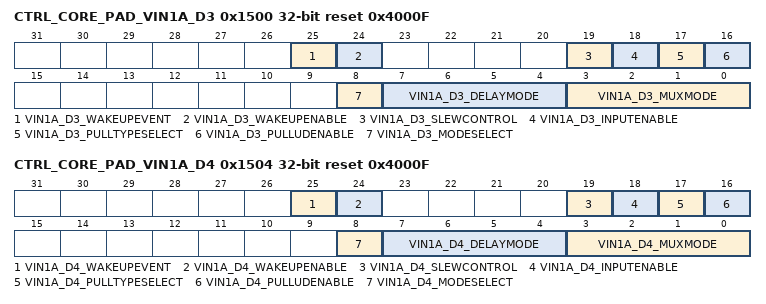
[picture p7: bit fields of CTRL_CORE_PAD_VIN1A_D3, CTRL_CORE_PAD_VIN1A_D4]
0x1500 CTRL_CORE_PAD_VIN1A_D3 reset 0x4000F
  [25] VIN1A_D3_WAKEUPEVENT ro
    values as CTRL_CORE_PAD_GPMC_A15.GPMC_A15_WAKEUPEVENT
  [24] VIN1A_D3_WAKEUPENABLE rw
    0=DISABLE (Wakeup is disabled); 1=ENABLE (Wakeup is enabled)
  [19] VIN1A_D3_SLEWCONTROL rw
    values as CTRL_CORE_PAD_GPMC_A15.GPMC_A15_SLEWCONTROL
  [18] VIN1A_D3_INPUTENABLE rw
    values as CTRL_CORE_PAD_GPMC_A15.GPMC_A15_INPUTENABLE
  [17] VIN1A_D3_PULLTYPESELECT rw
    values as CTRL_CORE_PAD_GPMC_A15.GPMC_A15_PULLTYPESELECT
  [16] VIN1A_D3_PULLUDENABLE rw
    values as CTRL_CORE_PAD_GPMC_A15.GPMC_A15_PULLUDENABLE
  [8] VIN1A_D3_MODESELECT rw — Selects between the Default IO Timing Mode and a Virtual or Manual IO Timing Mode. Refer to the device Data Manual for definition of the required settings for a given mode of operation. When this bit is 0b1, a Virtual IO Timing Mode can be selected via the DELAYMODE field of this register, as described in, Virtual IO Timing Modes. Manual IO Timing Modes are selected via the procedure described in , Manual IO Timing Modes.
    values as CTRL_CORE_PAD_GPMC_A15.GPMC_A15_MODESELECT
  [7:4] VIN1A_D3_DELAYMODE rw — This bit field selects the Virtual Timing Mode used when the MODESELECT bit is set to 0b1. See, Virtual IO Timing Modes for details.
  [3:0] VIN1A_D3_MUXMODE rw
    0=VIN1A_D3; 3=VOUT3_D4; 4=VOUT3_D20; 5=UART8_RTSN; 10=ECAP1_IN_PWM1_OUT; 12=PR1_PRU0_GPI0; 13=PR1_PRU0_GPO0; 14=GPIO3_7; 15=DRIVER OFF
0x1504 CTRL_CORE_PAD_VIN1A_D4 reset 0x4000F
  [25] VIN1A_D4_WAKEUPEVENT ro
    values as CTRL_CORE_PAD_GPMC_A15.GPMC_A15_WAKEUPEVENT
  [24] VIN1A_D4_WAKEUPENABLE rw
    0=DISABLE (Wakeup is disabled); 1=ENABLE (Wakeup is enabled)
  [19] VIN1A_D4_SLEWCONTROL rw
    values as CTRL_CORE_PAD_GPMC_A15.GPMC_A15_SLEWCONTROL
  [18] VIN1A_D4_INPUTENABLE rw
    values as CTRL_CORE_PAD_GPMC_A15.GPMC_A15_INPUTENABLE
  [17] VIN1A_D4_PULLTYPESELECT rw
    values as CTRL_CORE_PAD_GPMC_A15.GPMC_A15_PULLTYPESELECT
  [16] VIN1A_D4_PULLUDENABLE rw
    values as CTRL_CORE_PAD_GPMC_A15.GPMC_A15_PULLUDENABLE
  [8] VIN1A_D4_MODESELECT rw — Selects between the Default IO Timing Mode and a Virtual or Manual IO Timing Mode. Refer to the device Data Manual for definition of the required settings for a given mode of operation. When this bit is 0b1, a Virtual IO Timing Mode can be selected via the DELAYMODE field of this register, as described in, Virtual IO Timing Modes. Manual IO Timing Modes are selected via the procedure described in , Manual IO Timing Modes.
    values as CTRL_CORE_PAD_GPMC_A15.GPMC_A15_MODESELECT
  [7:4] VIN1A_D4_DELAYMODE rw — This bit field selects the Virtual Timing Mode used when the MODESELECT bit is set to 0b1. See, Virtual IO Timing Modes for details.
  [3:0] VIN1A_D4_MUXMODE rw
    0=VIN1A_D4; 3=VOUT3_D3; 4=VOUT3_D19; 10=EHRPWM1_SYNCI; 12=PR1_PRU0_GPI1; 13=PR1_PRU0_GPO1; 14=GPIO3_8; 15=DRIVER OFF
